# Daric register map
Vendor: Daric; Series: Daric; File version: 1.0
CPU: CM7 r1p2, little endian, MPU, FPU, vendor SysTick, 3 interrupt priority bits
Registers are 32-bit, access not given, reset 0x0 unless marked. A register's access mark holds for its fields unless they carry their own. Offsets are from the block's base; [hi:lo] are bit positions; lines under a group give offsets from that group; {n}, {i} and the like mark numbered series.

## SPIM0 — SPI Master 0
Base 0x50105000
Same registers: SPIM1 0x50106000, SPIM2 0x50107000, SPIM3 0x50108000
0x00 RX_CHANNEL group — UDMA RX Channel
  0x00 SADDR — RX Buffer Start Address
  0x04 SIZE — RX Buffer Size
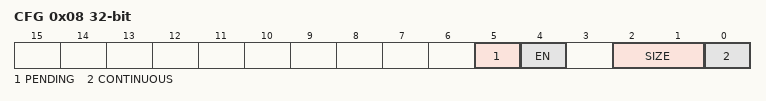
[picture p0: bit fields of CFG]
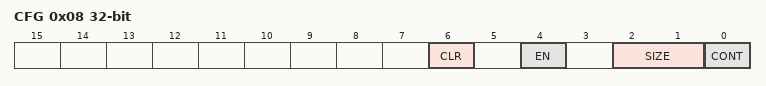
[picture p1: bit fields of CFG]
  0x08 CFG — RX Configuration
    [5] PENDING, [4] EN, [2:1] SIZE, [0] CONTINUOUS
0x10 TX_CHANNEL group — UDMA TX Channel
  0x00 SADDR — TX Buffer Start Address
  0x04 SIZE — TX Buffer Size
  0x08 CFG — TX Configuration
    [5] PENDING, [4] EN, [2:1] SIZE, [0] CONTINUOUS
0x20 CMD_CHANNEL group — UDMA CMD Channel
  0x00 SADDR — CMD Buffer Start Address
  0x04 SIZE — CMD Buffer Size
  0x08 CFG — CMD Configuration
    [5] PENDING, [4] EN, [2:1] SIZE, [0] CONTINUOUS

## I2C0 — I2C Master 0
Base 0x50109000
Same registers: I2C1 0x5010A000, I2C2 0x5010B000, I2C3 0x5010C000
0x00 RX_CHANNEL group — UDMA RX Channel
  0x00 SADDR — RX Buffer Start Address
  0x04 SIZE — RX Buffer Size
  0x08 CFG — RX Configuration
    [6] CLR, [4] EN, [2:1] SIZE, [0] CONT
0x10 TX_CHANNEL group — UDMA TX Channel
  0x00 SADDR — TX Buffer Start Address
  0x04 SIZE — TX Buffer Size
  0x08 CFG — TX Configuration
    [6] CLR, [4] EN, [2:1] SIZE, [0] CONT
0x20 CMD_CHANNEL group — UDMA CMD Channel
  0x00 SADDR — CMD Buffer Start Address
  0x04 SIZE — CMD Buffer Size
  0x08 CFG — CMD Configuration
    [6] CLR, [4] EN, [2:1] SIZE, [0] CONT
0x30 STATUS — I2C Status Register
0x34 SETUP — I2C Setup Register

## GPIO — General Purpose I/O
Base 0x5012F000
0x00 AFSEL_PAL
0x04 AFSEL_PAH
0x08 AFSEL_PBL
0x0C AFSEL_PBH
0x10 AFSEL_PCL
0x14 AFSEL_PCH
0x18 AFSEL_PDL
0x1C AFSEL_PDH
0x20 AFSEL_PEL
0x24 AFSEL_PEH
0x28 AFSEL_PFL
0x2C AFSEL_PFH
0x100 INTCR group
  {0x0+4j} INTCR{j} (j=0..7)
0x130 OUT_PA
0x134 OUT_PB
0x138 OUT_PC
0x13C OUT_PD
0x140 OUT_PE
0x144 OUT_PF
0x148 OE_PA
0x14C OE_PB
0x150 OE_PC
0x154 OE_PD
0x158 OE_PE
0x15C OE_PF
0x160 PU_PA
0x164 PU_PB
0x168 PU_PC
0x16C PU_PD
0x170 PU_PE
0x174 PU_PF
0x178 IN_PA
0x17C IN_PB
0x180 IN_PC
0x184 IN_PD
0x188 IN_PE
0x18C IN_PF
0x230 SCHM_PA
0x234 SCHM_PB
0x238 SCHM_PC
0x23C SCHM_PD
0x240 SCHM_PE
0x244 SCHM_PF
0x248 RATCLR_PA
0x24C RATCLR_PB
0x250 RATCLR_PC
0x254 RATCLR_PD
0x258 RATCLR_PE
0x25C RATCLR_PF
0x260 DRVSEL_PA
0x264 DRVSEL_PB
0x268 DRVSEL_PC
0x26C DRVSEL_PD
0x270 DRVSEL_PE
0x274 DRVSEL_PF

## ATIMER — Advanced Timer
Base 0x40043000
Same registers: ATIMER_AO 0x40063000
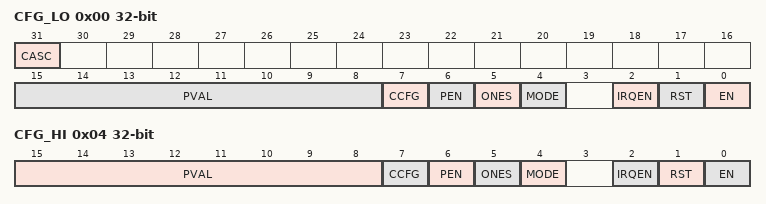
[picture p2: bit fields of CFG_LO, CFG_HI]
0x00 CFG_LO — Timer Low Configuration register
  [31] CASC — Timer low and Timer high 64-bit cascaded mode enable bit
  [15:8] PVAL — Timer low prescaler value
  [7] CCFG — Timer low clock source configuration
  [6] PEN — Timer low prescaler enable bit
  [5] ONES — Timer low one shot configuration
  [4] MODE — Timer low continuous mode configuration
  [2] IRQEN — Timer low interrupt generation on compare match enable
  [1] RST — Timer low reset, cleared after the reset happened
  [0] EN — Timer enable (starts counting) bit
0x04 CFG_HI — Timer High Configuration register
  [15:8] PVAL — Timer High prescaler value
  [7] CCFG — Timer low clock source configuration
  [6] PEN — Timer High prescaler enable bit
  [5] ONES — Timer High one shot configuration
  [4] MODE — Timer High continuous mode configuration
  [2] IRQEN — Timer High interrupt generation on compare match enable
  [1] RST — Timer High reset, cleared after the reset happened
  [0] EN — Timer enable (starts counting) bit
0x08 CNT_LO — Timer Low counter value register
0x0C CNT_HI — Timer High counter value register
0x10 CMP_LO — Timer Low comparator value register
0x14 CMP_HI — Timer High comparator value register
0x18 START_LO — Start Timer Low counting register
  [0] S — Timer start command
0x1C START_HI — Start Timer High counting register
  [0] S — Timer start command
0x20 RESET_LO — Reset Timer Low counter register
  [0] R — Timer reset command
0x24 RESET_HI — Reset Timer High counter register
  [0] R — Timer reset command
